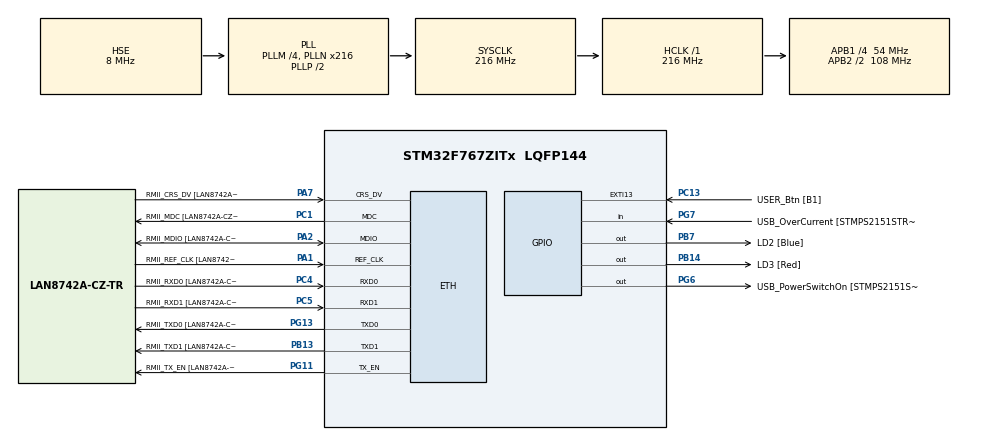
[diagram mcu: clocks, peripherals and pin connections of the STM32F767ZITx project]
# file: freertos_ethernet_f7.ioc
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CORTEX_M7.ART_ACCLERATOR_ENABLE=1
CORTEX_M7.CPU_DCache=Enabled
CORTEX_M7.CPU_ICache=Enabled
CORTEX_M7.PREFETCH_ENABLE=1
ETH.MediaInterface=ETH_MEDIA_INTERFACE_RMII
ETH.PHY_Name=LAN8742A_PHY_ADDRESS
ETH.PHY_Value=0
ETH.PhyAddress=0
FREERTOS.INCLUDE_xTaskGetCurrentTaskHandle=1
FREERTOS.Tasks01=defaultTask,0,128,StartDefaultTask,Default,NULL
FREERTOS.configUSE_COUNTING_SEMAPHORES=1
FREERTOS.configUSE_RECURSIVE_MUTEXES=1
Mcu.Family=STM32F7
Mcu.Name=STM32F767ZITx
Mcu.Package=LQFP144
NVIC.PriorityGroup=NVIC_PRIORITYGROUP_4
NVIC.TIM6_DAC_IRQn=true\:0\:0\:false\:false\:true\:false\:false\:true
NVIC.TimeBase=TIM6_DAC_IRQn
NVIC.TimeBaseIP=TIM6
PA1.GPIO_Label=RMII_REF_CLK [LAN8742A-CZ-TR_REFCLK0]
PA1.Mode=RMII
PA1.Signal=ETH_REF_CLK
PA13.GPIO_Label=TMS
PA13.Mode=Serial_Wire
PA13.Signal=SYS_JTMS-SWDIO
PA14.GPIO_Label=TCK
PA14.Mode=Serial_Wire
PA14.Signal=SYS_JTCK-SWCLK
PA2.GPIO_Label=RMII_MDIO [LAN8742A-CZ-TR_MDIO]
PA2.Mode=RMII
PA2.Signal=ETH_MDIO
PA7.GPIO_Label=RMII_CRS_DV [LAN8742A-CZ-TR_CRS_DV]
PA7.Mode=RMII
PA7.Signal=ETH_CRS_DV
PB13.GPIO_Label=RMII_TXD1 [LAN8742A-CZ-TR_TXD1]
PB13.Mode=RMII
PB13.Signal=ETH_TXD1
PB14.GPIO_Label=LD3 [Red]
PB14.Signal=GPIO_Output
PB3.GPIO_Label=SWO
PB3.Signal=SYS_JTDO-SWO
PB7.GPIO_Label=LD2 [Blue]
PB7.Signal=GPIO_Output
PC1.GPIO_Label=RMII_MDC [LAN8742A-CZ-TR_MDC]
PC1.Mode=RMII
PC1.Signal=ETH_MDC
PC13.GPIO_Label=USER_Btn [B1]
PC13.Signal=GPXTI13
PC14/OSC32_IN.Mode=LSE-External-Oscillator
PC14/OSC32_IN.Signal=RCC_OSC32_IN
PC15/OSC32_OUT.Mode=LSE-External-Oscillator
PC15/OSC32_OUT.Signal=RCC_OSC32_OUT
PC4.GPIO_Label=RMII_RXD0 [LAN8742A-CZ-TR_RXD0]
PC4.Mode=RMII
PC4.Signal=ETH_RXD0
PC5.GPIO_Label=RMII_RXD1 [LAN8742A-CZ-TR_RXD1]
PC5.Mode=RMII
PC5.Signal=ETH_RXD1
PG11.GPIO_Label=RMII_TX_EN [LAN8742A-CZ-TR_TXEN]
PG11.Mode=RMII
PG11.Signal=ETH_TX_EN
PG13.GPIO_Label=RMII_TXD0 [LAN8742A-CZ-TR_TXD0]
PG13.Mode=RMII
PG13.Signal=ETH_TXD0
PG6.GPIO_Label=USB_PowerSwitchOn [STMPS2151STR_EN]
PG6.Signal=GPIO_Output
PG7.GPIO_Label=USB_OverCurrent [STMPS2151STR_FAULT]
PG7.Signal=GPIO_Input
PH0/OSC_IN.GPIO_Label=MCO [STM32F103CBT6_PA8]
PH0/OSC_IN.Mode=HSE-External-Clock-Source
PH0/OSC_IN.Signal=RCC_OSC_IN
PH1/OSC_OUT.Mode=HSE-External-Clock-Source
PH1/OSC_OUT.Signal=RCC_OSC_OUT
ProjectManager.HeapSize=0x200
ProjectManager.StackSize=0x400
ProjectManager.TargetToolchain=STM32CubeIDE
RCC.48MHZClocksFreq_Value=24000000
RCC.AHBFreq_Value=216000000
RCC.APB1CLKDivider=RCC_HCLK_DIV4
RCC.APB1Freq_Value=54000000
RCC.APB1TimFreq_Value=108000000
RCC.APB2CLKDivider=RCC_HCLK_DIV2
RCC.APB2Freq_Value=108000000
RCC.APB2TimFreq_Value=216000000
RCC.CortexFreq_Value=216000000
RCC.HCLKFreq_Value=216000000
RCC.HSE_VALUE=8000000
RCC.HSI_VALUE=16000000
RCC.PLLM=4
RCC.PLLMUL=RCC_PLL_MUL9
RCC.PLLN=216
RCC.PLLQ=9
RCC.PLLSourceVirtual=RCC_PLLSOURCE_HSE
RCC.PRESCALERUSB=RCC_USBCLKSOURCE_PLL_DIV1_5
RCC.SYSCLKFreq_VALUE=216000000
RCC.SYSCLKSource=RCC_SYSCLKSOURCE_PLLCLK
RCC.SYSCLKSourceVirtual=RCC_SYSCLKSOURCE_PLLCLK
RCC.USBFreq_Value=48000000
RCC.VCOOutputFreq_Value=432000000
VP_FREERTOS_VS_CMSIS_V1.Mode=CMSIS_V1
VP_RNG_VS_RNG.Mode=RNG_Activate
VP_SYS_VS_tim6.Mode=TIM6
board=NUCLEO-F767ZI

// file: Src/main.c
/* USER CODE BEGIN Header */
/**
 ******************************************************************************
 * @file           : main.c
 * @brief          : Main program body
 ******************************************************************************
 * @attention
 *
 * <h2><center>&copy; Copyright (c) 2019 STMicroelectronics.
 * All rights reserved.</center></h2>
 *
 * This software component is licensed by ST under BSD 3-Clause license,
 * the "License"; You may not use this file except in compliance with the
 * License. You may obtain a copy of the License at:
 *                        opensource.org/licenses/BSD-3-Clause
 *
 ******************************************************************************
 */
/* USER CODE END Header */

#include "main.h"
#include "cmsis_os.h"
#include "eth.h"
#include "rng.h"
#include "gpio.h"

/* USER CODE BEGIN Includes */
#include "FreeRTOS_IP.h"
/* USER CODE END Includes */

/* USER CODE BEGIN PV */

/* The MAC address array is not declared const as the MAC address will
normally be read from an EEPROM and not hard coded (in real deployed
applications).*/
uint8_t ucMACAddress[ 6 ] = { 0x00, 0x80, 0xE1, 0x00, 0x00, 0x00 };

/* Define the network addressing.  These parameters will be used if either
ipconfigUDE_DHCP is 0 or if ipconfigUSE_DHCP is 1 but DHCP auto configuration
failed. */
static const uint8_t ucIPAddress[ 4 ] = { 192, 168, 2, 12 };
static const uint8_t ucNetMask[ 4 ] = { 255, 255, 255, 0 };
static const uint8_t ucGatewayAddress[ 4 ] = { 192, 168, 2, 1 };

/* The following is the address of an OpenDNS server. */
static const uint8_t ucDNSServerAddress[ 4 ] = { 8, 8, 8, 8 };

/* USER CODE END PV */

void SystemClock_Config(void);
void MX_FREERTOS_Init(void);

int main(void)
{

	/* Enable I-Cache---------------------------------------------------------*/
	SCB_EnableICache();

	/* Enable D-Cache---------------------------------------------------------*/
	SCB_EnableDCache();

	/* MCU Configuration--------------------------------------------------------*/

	/* Reset of all peripherals, Initializes the Flash interface and the Systick. */
	HAL_Init();

	/* Configure the system clock */
	SystemClock_Config();

	/* Initialize all configured peripherals */
	MX_GPIO_Init();
	#if ( globalUSE_DEFAULT_ETH_INIT != 0 )
	MX_ETH_Init();
	#endif /* globalUSE_DEFAULT_ETH_INIT */
	MX_RNG_Init();
	/* USER CODE BEGIN 2 */
	FreeRTOS_IPInit( ucIPAddress,
			ucNetMask,
			ucGatewayAddress,
			ucDNSServerAddress,
			ucMACAddress );
	/* USER CODE END 2 */

	/* Call init function for freertos objects (in freertos.c) */
	MX_FREERTOS_Init();

	/* Start scheduler */
	osKernelStart();

	/* We should never get here as control is now taken by the scheduler */

	/* Infinite loop */
	while (1)
	{

	}
}

void SystemClock_Config(void)
{
	RCC_OscInitTypeDef RCC_OscInitStruct = {0};
	RCC_ClkInitTypeDef RCC_ClkInitStruct = {0};
	RCC_PeriphCLKInitTypeDef PeriphClkInitStruct = {0};

	/** Configure LSE Drive Capability
	 */
	HAL_PWR_EnableBkUpAccess();
	/** Configure the main internal regulator output voltage
	 */
	__HAL_RCC_PWR_CLK_ENABLE();
	__HAL_PWR_VOLTAGESCALING_CONFIG(PWR_REGULATOR_VOLTAGE_SCALE1);
	/** Initializes the CPU, AHB and APB busses clocks
	 */
	RCC_OscInitStruct.OscillatorType = RCC_OSCILLATORTYPE_HSE;
	RCC_OscInitStruct.HSEState = RCC_HSE_BYPASS;
	RCC_OscInitStruct.PLL.PLLState = RCC_PLL_ON;
	RCC_OscInitStruct.PLL.PLLSource = RCC_PLLSOURCE_HSE;
	RCC_OscInitStruct.PLL.PLLM = 4;
	RCC_OscInitStruct.PLL.PLLN = 216;
	RCC_OscInitStruct.PLL.PLLP = RCC_PLLP_DIV2;
	RCC_OscInitStruct.PLL.PLLQ = 9;
	if (HAL_RCC_OscConfig(&RCC_OscInitStruct) != HAL_OK)
	{
		Error_Handler();
	}
	/** Activate the Over-Drive mode
	 */
	if (HAL_PWREx_EnableOverDrive() != HAL_OK)
	{
		Error_Handler();
	}
	/** Initializes the CPU, AHB and APB busses clocks
	 */
	RCC_ClkInitStruct.ClockType = RCC_CLOCKTYPE_HCLK|RCC_CLOCKTYPE_SYSCLK
			|RCC_CLOCKTYPE_PCLK1|RCC_CLOCKTYPE_PCLK2;
	RCC_ClkInitStruct.SYSCLKSource = RCC_SYSCLKSOURCE_PLLCLK;
	RCC_ClkInitStruct.AHBCLKDivider = RCC_SYSCLK_DIV1;
	RCC_ClkInitStruct.APB1CLKDivider = RCC_HCLK_DIV4;
	RCC_ClkInitStruct.APB2CLKDivider = RCC_HCLK_DIV2;

	if (HAL_RCC_ClockConfig(&RCC_ClkInitStruct, FLASH_LATENCY_7) != HAL_OK)
	{
		Error_Handler();
	}
	PeriphClkInitStruct.PeriphClockSelection = RCC_PERIPHCLK_CLK48;
	PeriphClkInitStruct.Clk48ClockSelection = RCC_CLK48SOURCE_PLL;
	if (HAL_RCCEx_PeriphCLKConfig(&PeriphClkInitStruct) != HAL_OK)
	{
		Error_Handler();
	}
}

void HAL_TIM_PeriodElapsedCallback(TIM_HandleTypeDef *htim)
{
	if (htim->Instance == TIM6) {
		HAL_IncTick();
	}
}

void Error_Handler(void)
{
}

/************************ (C) COPYRIGHT STMicroelectronics *****END OF FILE****/

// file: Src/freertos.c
/* USER CODE BEGIN Header */
/**
 ******************************************************************************
 * File Name          : freertos.c
 * Description        : Code for freertos applications
 ******************************************************************************
 * @attention
 *
 * <h2><center>&copy; Copyright (c) 2019 STMicroelectronics.
 * All rights reserved.</center></h2>
 *
 * This software component is licensed by ST under Ultimate Liberty license
 * SLA0044, the "License"; You may not use this file except in compliance with
 * the License. You may obtain a copy of the License at:
 *                             www.st.com/SLA0044
 *
 ******************************************************************************
 */
/* USER CODE END Header */

#include "FreeRTOS.h"
#include "task.h"
#include "main.h"
#include "cmsis_os.h"

/* USER CODE BEGIN Includes */
#include "utils.h"
/* USER CODE END Includes */

osThreadId defaultTaskHandle;

void StartDefaultTask(void const * argument);

void MX_FREERTOS_Init(void); /* (MISRA C 2004 rule 8.1) */

void MX_FREERTOS_Init(void) {

	/* Create the thread(s) */
	/* definition and creation of defaultTask */
	osThreadDef(defaultTask, StartDefaultTask, osPriorityNormal, 0, 128);
	defaultTaskHandle = osThreadCreate(osThread(defaultTask), NULL);

}

void StartDefaultTask(void const * argument)
{

	/* USER CODE BEGIN StartDefaultTask */
	vUtilsInit();
	/* Infinite loop */
	for(;;)
	{
		osDelay(1);
	}
	/* USER CODE END StartDefaultTask */
}

/************************ (C) COPYRIGHT STMicroelectronics *****END OF FILE****/
